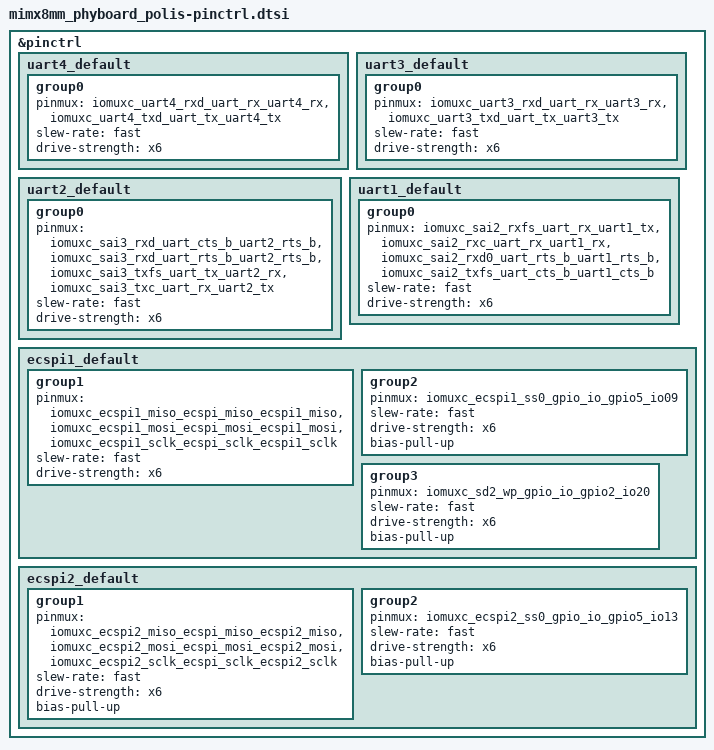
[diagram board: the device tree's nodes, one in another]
/*
 * Copyright (c) 2022-2024 PHYTEC Messtechnik GmbH
 *
 * SPDX-License-Identifier: Apache-2.0
 */

#include <nxp/nxp_imx/mimx8mm6dvtlz-pinctrl.dtsi>

&pinctrl {
	uart4_default: uart4_default {
		group0 {
			pinmux = <&iomuxc_uart4_rxd_uart_rx_uart4_rx>,
				<&iomuxc_uart4_txd_uart_tx_uart4_tx>;
			slew-rate = "fast";
			drive-strength = "x6";
		};
	};

	uart3_default: uart3_default {
		group0 {
			pinmux = <&iomuxc_uart3_rxd_uart_rx_uart3_rx>,
				<&iomuxc_uart3_txd_uart_tx_uart3_tx>;
			slew-rate = "fast";
			drive-strength = "x6";
		};
	};

	uart2_default: uart2_default {
		group0 {
			pinmux = <&iomuxc_sai3_rxd_uart_cts_b_uart2_rts_b>,
				<&iomuxc_sai3_rxd_uart_rts_b_uart2_rts_b>,
				<&iomuxc_sai3_txfs_uart_tx_uart2_rx>,
				<&iomuxc_sai3_txc_uart_rx_uart2_tx>;
			slew-rate = "fast";
			drive-strength = "x6";
		};
	};

	uart1_default: uart1_default {
		group0 {
			pinmux = <&iomuxc_sai2_rxfs_uart_rx_uart1_tx>,
				<&iomuxc_sai2_rxc_uart_rx_uart1_rx>,
				<&iomuxc_sai2_rxd0_uart_rts_b_uart1_rts_b>,
				<&iomuxc_sai2_txfs_uart_cts_b_uart1_cts_b>;
			slew-rate = "fast";
			drive-strength = "x6";
		};
	};

	ecspi1_default: ecspi1_default {
		group1 {
			pinmux = <&iomuxc_ecspi1_miso_ecspi_miso_ecspi1_miso>,
					 <&iomuxc_ecspi1_mosi_ecspi_mosi_ecspi1_mosi>,
					 <&iomuxc_ecspi1_sclk_ecspi_sclk_ecspi1_sclk>;
			slew-rate = "fast";
			drive-strength = "x6";
		};
		group2 {
			pinmux = <&iomuxc_ecspi1_ss0_gpio_io_gpio5_io09>;
			slew-rate = "fast";
			drive-strength = "x6";
			bias-pull-up;
		};
		group3 {
			pinmux = <&iomuxc_sd2_wp_gpio_io_gpio2_io20>;
			slew-rate = "fast";
			drive-strength = "x6";
			bias-pull-up;
		};
	};

	ecspi2_default: ecspi2_default {
		group1 {
			pinmux = <&iomuxc_ecspi2_miso_ecspi_miso_ecspi2_miso>,
					 <&iomuxc_ecspi2_mosi_ecspi_mosi_ecspi2_mosi>,
					 <&iomuxc_ecspi2_sclk_ecspi_sclk_ecspi2_sclk>;
			slew-rate = "fast";
			drive-strength = "x6";
			bias-pull-up;
		};
		group2 {
			pinmux = <&iomuxc_ecspi2_ss0_gpio_io_gpio5_io13>;
			slew-rate = "fast";
			drive-strength = "x6";
			bias-pull-up;
		};
	};
};
